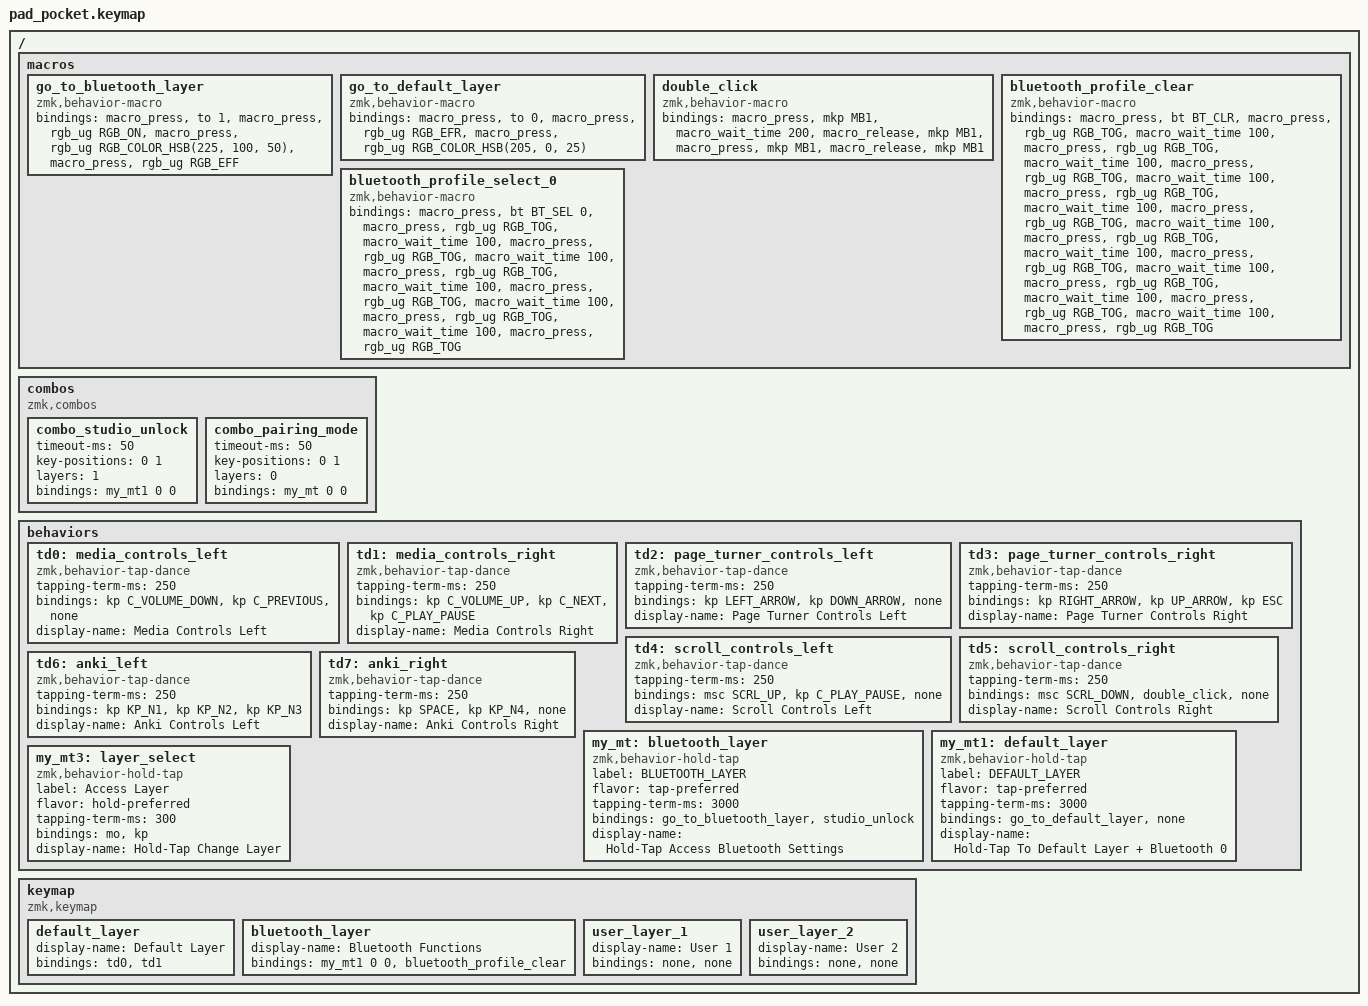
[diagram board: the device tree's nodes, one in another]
#include <behaviors.dtsi>
#include <dt-bindings/zmk/keys.h>
#include <dt-bindings/zmk/bt.h>
#include <dt-bindings/zmk/rgb.h>
#include <dt-bindings/zmk/pointing.h>

#define ZMK_POINTING_DEFAULT_SCRL_VAL 5

/ {
     macros {
        go_to_bluetooth_layer: go_to_bluetooth_layer {
            compatible = "zmk,behavior-macro";
            #binding-cells = <0>;
            bindings = <&macro_press &to 1>, <&macro_press &rgb_ug RGB_ON>, <&macro_press &rgb_ug RGB_COLOR_HSB(225, 100, 50)>, <&macro_press &rgb_ug RGB_EFF>; 
        };

        go_to_default_layer: go_to_default_layer {
            compatible = "zmk,behavior-macro";
            #binding-cells = <0>;
            bindings = <&macro_press &to 0>, <&macro_press &rgb_ug RGB_EFR>, <&macro_press &rgb_ug RGB_COLOR_HSB(205, 0, 25)>; 
        };

        double_click: double_click {
            compatible = "zmk,behavior-macro";
            #binding-cells = <0>;
            bindings = <&macro_press &mkp MB1>, <&macro_wait_time 200>, <&macro_release &mkp MB1>, <&macro_press &mkp MB1>, <&macro_release &mkp MB1>; 
        };

        bluetooth_profile_clear: bluetooth_profile_clear {
            compatible = "zmk,behavior-macro";
            #binding-cells = <0>;
            bindings = <&macro_press &bt BT_CLR>
            , <&macro_press &rgb_ug RGB_TOG>
            , <&macro_wait_time 100>
            , <&macro_press &rgb_ug RGB_TOG>
            ,  <&macro_wait_time 100>
            , <&macro_press &rgb_ug RGB_TOG>
            , <&macro_wait_time 100>
            , <&macro_press &rgb_ug RGB_TOG>
            , <&macro_wait_time 100>
            , <&macro_press &rgb_ug RGB_TOG>
            , <&macro_wait_time 100>
            , <&macro_press &rgb_ug RGB_TOG>
            , <&macro_wait_time 100>
            , <&macro_press &rgb_ug RGB_TOG>
            , <&macro_wait_time 100>
            , <&macro_press &rgb_ug RGB_TOG>
            , <&macro_wait_time 100>
            , <&macro_press &rgb_ug RGB_TOG>
            , <&macro_wait_time 100>
            , <&macro_press &rgb_ug RGB_TOG>; 
        };

        bluetooth_profile_select_0: bluetooth_profile_select_0 {
            compatible = "zmk,behavior-macro";
            #binding-cells = <0>;
            bindings = <&macro_press &bt BT_SEL 0>
            , <&macro_press &rgb_ug RGB_TOG>
            , <&macro_wait_time 100>
            , <&macro_press &rgb_ug RGB_TOG>
            , <&macro_wait_time 100>
            , <&macro_press &rgb_ug RGB_TOG>
            , <&macro_wait_time 100>
            , <&macro_press &rgb_ug RGB_TOG>
            , <&macro_wait_time 100>
            , <&macro_press &rgb_ug RGB_TOG>
            , <&macro_wait_time 100>
            , <&macro_press &rgb_ug RGB_TOG>; 
        };
    };

    combos {
        compatible = "zmk,combos";
        combo_studio_unlock {
            timeout-ms = <50>;
            key-positions = <0 1>;
            layers = <1>;
            bindings = <&my_mt1 0 0>;
        };

        combo_pairing_mode {
            timeout-ms = <50>;
            key-positions = <0 1>;
            layers = <0>;
            bindings = <&my_mt 0 0>;
        };
    };

    behaviors {
        td0: media_controls_left {
            compatible = "zmk,behavior-tap-dance";
            #binding-cells = <0>;
            tapping-term-ms = <250>;
            bindings = <&kp C_VOLUME_DOWN>, <&kp C_PREVIOUS>, <&none>;
            display-name = "Media Controls Left";
        };

        td1: media_controls_right {
            compatible = "zmk,behavior-tap-dance";
            #binding-cells = <0>;
            tapping-term-ms = <250>;
            bindings = <&kp C_VOLUME_UP>, <&kp C_NEXT>, <&kp C_PLAY_PAUSE>;
            display-name = "Media Controls Right";
        };

        td2: page_turner_controls_left {
            compatible = "zmk,behavior-tap-dance";
            #binding-cells = <0>;
            tapping-term-ms = <250>;
            bindings = <&kp LEFT_ARROW>, <&kp DOWN_ARROW>, <&none>;
            display-name = "Page Turner Controls Left";
        };

        td3: page_turner_controls_right {
            compatible = "zmk,behavior-tap-dance";
            #binding-cells = <0>;
            tapping-term-ms = <250>;
            bindings = <&kp RIGHT_ARROW>, <&kp UP_ARROW>, <&kp ESC>;
            display-name = "Page Turner Controls Right";
        };

        td4: scroll_controls_left {
            compatible = "zmk,behavior-tap-dance";
            #binding-cells = <0>;
            tapping-term-ms = <250>;
            bindings = <&msc SCRL_UP>, <&kp C_PLAY_PAUSE>, <&none>;
            display-name = "Scroll Controls Left";
        };

        td5: scroll_controls_right {
            compatible = "zmk,behavior-tap-dance";
            #binding-cells = <0>;
            tapping-term-ms = <250>;
            bindings = <&msc SCRL_DOWN>, <&double_click>, <&none>;
            display-name = "Scroll Controls Right";
        };

        td6: anki_left {
            compatible = "zmk,behavior-tap-dance";
            #binding-cells = <0>;
            tapping-term-ms = <250>;
            bindings = <&kp KP_N1>, <&kp KP_N2>, <&kp KP_N3>;
            display-name = "Anki Controls Left";
        };

        td7: anki_right {
            compatible = "zmk,behavior-tap-dance";
            #binding-cells = <0>;
            tapping-term-ms = <250>;
            bindings = <&kp SPACE>, <&kp KP_N4>, <&none>;
            display-name = "Anki Controls Right";
        };

        my_mt: bluetooth_layer {
            compatible = "zmk,behavior-hold-tap";
            label = "BLUETOOTH_LAYER";
            #binding-cells = <2>;
            flavor = "tap-preferred";
            tapping-term-ms = <3000>;
            bindings = <&go_to_bluetooth_layer>, <&studio_unlock>;
            display-name = "Hold-Tap Access Bluetooth Settings";
        };

        my_mt1: default_layer {
            compatible = "zmk,behavior-hold-tap";
            label = "DEFAULT_LAYER";
            #binding-cells = <2>;
            flavor = "tap-preferred";
            tapping-term-ms = <3000>;
            bindings = <&go_to_default_layer>, <&none>;
            display-name = "Hold-Tap To Default Layer + Bluetooth 0";
        };

        my_mt3: layer_select {
            compatible = "zmk,behavior-hold-tap";
            label = "Access Layer";
            #binding-cells = <2>;
            flavor = "hold-preferred";
            tapping-term-ms = <300>;
            bindings = <&mo>, <&kp>;
            display-name = "Hold-Tap Change Layer";
        };
    };

    keymap {
        compatible = "zmk,keymap";

        default_layer { // Layer 0
            display-name = "Default Layer";
            // -------------------------------------
            //       |     Vol -    |     Vol +     |
            bindings = <
                &td0
                &td1
            >;
        };

        bluetooth_layer { // Layer 1
            display-name = "Bluetooth Functions";
            // -------------------------------------
            //       |     BT 0     |     BT 1     |
            bindings = <
                &my_mt1 0 0
                &bluetooth_profile_clear
            >;
        };

        user_layer_1 { // Layer 2
            display-name = "User 1";
            // -------------------------------------
            //       |     None     |     None     |
            bindings = <
                &none
                &none
            >;
        };

        user_layer_2 { // Layer 3
            display-name = "User 2";
            // -------------------------------------
            //       |     None     |     None     |
            bindings = <
                &none
                &none
            >;
        };
    };
 };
